# STM32H743 register map
File version: 2.4
CPU: CM7 r0p1, little endian, MPU, FPU, 4 interrupt priority bits
Registers are 32-bit, read-write, reset 0x0 unless marked. A register's access mark holds for its fields unless they carry their own. Offsets are from the block's base; [hi:lo] are bit positions.

## DMA2D — DMA2D（Chrom-Art 2D DMA 加速器）
Base 0x52001000
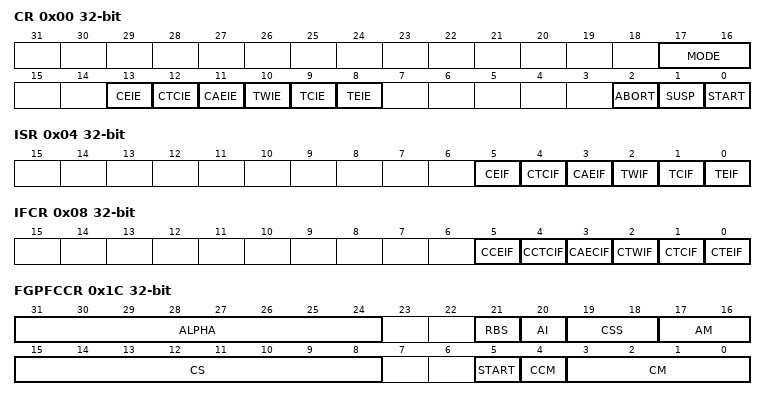
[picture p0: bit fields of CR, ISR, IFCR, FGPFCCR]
0x00 CR — DMA2D 控制寄存器
  [17:16] MODE — DMA2D 模式 此位由软件置位和清零。传输进行期间不可修改。
  [13] CEIE — 配置错误中断使能 此位由软件置位和清零。
  [12] CTCIE — CLUT 传输完成中断使能 此位由软件置位和清零。
  [11] CAEIE — CLUT 访问错误中断使能 此位由软件置位和清零。
  [10] TWIE — 传输水印中断使能 此位由软件置位和清零。
  [9] TCIE — 传输完成中断使能 此位由软件置位和清零。
  [8] TEIE — 传输错误中断使能 此位由软件置位和清零。
  [2] ABORT — 中止 将此位置 1 可中止当前传输。此位由软件置位，并在 START 位被硬件清零时由硬件自动清零。
  [1] SUSP — 暂停 将此位置 1 可暂停当前传输。此位由软件置位和清零。当 START 位被硬件清零时，此位由硬件自动清零。
  [0] START — 启动 将此位置 1 可根据各配置寄存器中加载的参数启动 DMA2D 传输
0x04 ISR ro — DMA2D 中断状态寄存器
  [5] CEIF — 配置错误中断标志 当 DMA2D_CR、DMA2DFGPFCCR 或 DMA2D_BGPFCCR 的 START 位置 1 但配置有误时，此位置 1。
  [4] CTCIF — CLUT 传输完成中断标志 当 CLUT 从系统存储区复制到 DMA2D 内部存储器完成时，此位置 1。
  [3] CAEIF — CLUT 访问错误中断标志 当 CLUT 正在从系统存储器自动复制到 DMA2D 内部存储器期间，CPU 访问了 CLUT 时，此位置 1。
  [2] TWIF — 传输水印中断标志 当水印行的最后一个像素传输完成时，此位置 1。
  [1] TCIF — 传输完成中断标志 当 DMA2D 传输操作完成（仅限数据传输）时，此位置 1。
  [0] TEIF — 传输错误中断标志 当 DMA 传输（数据传输或自动 CLUT 加载）期间发生错误时，此位置 1。
0x08 IFCR — DMA2D 中断标志清零寄存器
  [5] CCEIF — 清除配置错误中断标志 将此位写 1 可清零 DMA2D_ISR 寄存器中的 CEIF 标志
  [4] CCTCIF — 清除 CLUT 传输完成中断标志 将此位写 1 可清零 DMA2D_ISR 寄存器中的 CTCIF 标志
  [3] CAECIF — 清除 CLUT 访问错误中断标志 将此位写 1 可清零 DMA2D_ISR 寄存器中的 CAEIF 标志
  [2] CTWIF — 清除传输水印中断标志 将此位写 1 可清零 DMA2D_ISR 寄存器中的 TWIF 标志
  [1] CTCIF — 清除传输完成中断标志 将此位写 1 可清零 DMA2D_ISR 寄存器中的 TCIF 标志
  [0] CTEIF — 清除传输错误中断标志 将此位写 1 可清零 DMA2D_ISR 寄存器中的 TEIF 标志
0x0C FGMAR — DMA2D 前景层存储器地址寄存器
  [31:0] MA — 存储器地址 前景图像数据的存放地址。此寄存器仅在数据传输禁用时可写。一旦数据传输开始，此寄存器即为只读。地址对齐方式必须与所选图像格式匹配，例如：32 位每像素格式必须 32 位对齐，16 位每像素格式必须 16 位对齐，4 位每像素格式必须 8 位对齐。
0x10 FGOR — DMA2D 前景层偏移寄存器
  [13:0] LO — 行偏移 前景层的行偏移量，以像素为单位。该值用于生成地址，在每行末尾累加以确定下一行的起始地址。这些位仅在数据传输禁用时可写。一旦数据传输开始，即变为只读。若图像格式为 4 位每像素，行偏移必须为偶数。
0x14 BGMAR — DMA2D 背景层存储器地址寄存器
  [31:0] MA — 存储器地址 背景图像数据的存放地址。此寄存器仅在数据传输禁用时可写。一旦数据传输开始，此寄存器即为只读。地址对齐方式必须与所选图像格式匹配，例如：32 位每像素格式必须 32 位对齐，16 位每像素格式必须 16 位对齐，4 位每像素格式必须 8 位对齐。
0x18 BGOR — DMA2D 背景层偏移寄存器
  [13:0] LO — 行偏移 背景图像的行偏移量，以像素为单位。该值用于地址生成，在每行末尾累加以确定下一行的起始地址。这些位仅在数据传输禁用时可写。一旦数据传输开始，即变为只读。若图像格式为 4 位每像素，行偏移必须为偶数。
0x1C FGPFCCR — DMA2D 前景层像素格式转换控制寄存器
  [31:24] ALPHA — Alpha 值 这些位定义一个固定的 Alpha 通道值，根据 AM[1:0] 位所选的 Alpha 模式，该值可替换原始 Alpha 值或与原始 Alpha 值相乘。这些位仅在数据传输禁用时可写。一旦传输开始，即变为只读。
  [21] RBS — 红蓝交换 此位允许交换 R 和 B 通道以支持 BGR 或 ABGR 颜色格式。一旦传输开始，此位即为只读。
  [20] AI — Alpha 取反 此位将 Alpha 值取反。一旦传输开始，此位即为只读。
  [19:18] CSS — 色度子采样 这些位定义 YCbCr 颜色模式下的色度子采样模式。一旦传输开始，这些位即为只读。其他值：无意义
  [17:16] AM — Alpha 模式 这些位选择前景图像使用的 Alpha 通道值。仅在数据传输禁用时可写。一旦传输开始，即变为只读。其他配置：无意义
  [15:8] CS — CLUT 大小 这些位定义前景图像所用 CLUT 的大小。一旦 CLUT 传输开始，此字段即为只读。CLUT 条目数量等于 CS[7:0] + 1。
  [5] START — 启动 将此位置 1 可启动 CLUT 的自动加载。此位在以下情况下由硬件自动清零：传输结束时；用户应用程序通过置位 DMA2D_CR 中的 ABORT 位中止传输时；发生传输错误时；由于配置错误或另一传输操作（数据传输或后台 CLUT 自动传输）正在进行而导致传输未能启动时。
  [4] CCM — CLUT 颜色模式 此位定义 CLUT 的颜色格式。仅在传输禁用时可写。一旦 CLUT 传输开始，此位即变为只读。
  [3:0] CM — 颜色模式 这些位定义前景图像的颜色格式。仅在数据传输禁用时可写。一旦传输开始，即变为只读。其他值：无意义
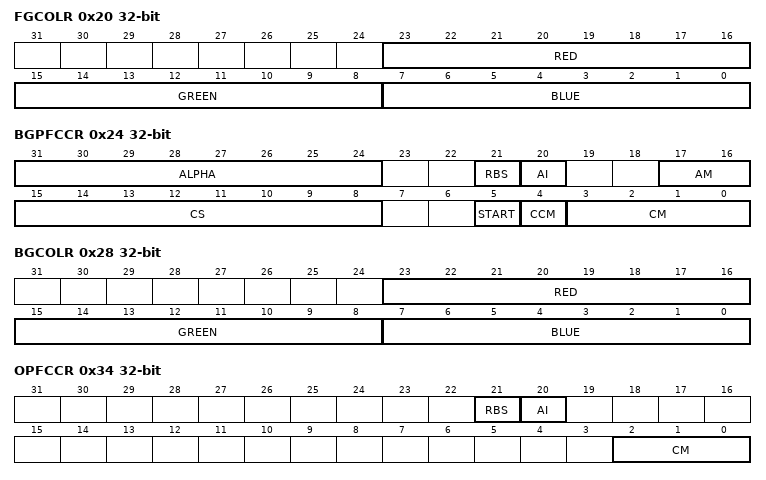
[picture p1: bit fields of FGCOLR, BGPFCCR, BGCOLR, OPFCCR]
0x20 FGCOLR — DMA2D 前景层颜色寄存器
  [23:16] RED — 红色分量 这些位定义前景图像在 A4 或 A8 模式下的红色分量值。仅在数据传输禁用时可写。一旦传输开始，即变为只读。
  [15:8] GREEN — 绿色分量 这些位定义前景图像在 A4 或 A8 模式下的绿色分量值。仅在数据传输禁用时可写。一旦传输开始，即变为只读。
  [7:0] BLUE — 蓝色分量 这些位定义前景图像在 A4 或 A8 模式下的蓝色分量值。仅在数据传输禁用时可写。一旦传输开始，即变为只读。
0x24 BGPFCCR — DMA2D 背景层像素格式转换控制寄存器
  [31:24] ALPHA — Alpha 值 这些位定义一个固定的 Alpha 通道值，根据 AM[1:0] 位所选的 Alpha 模式，该值可替换原始 Alpha 值或与原始 Alpha 值相乘。这些位仅在数据传输禁用时可写。一旦传输开始，即变为只读。
  [21] RBS — 红蓝交换 此位允许交换 R 和 B 通道以支持 BGR 或 ABGR 颜色格式。一旦传输开始，此位即为只读。
  [20] AI — Alpha 取反 此位将 Alpha 值取反。一旦传输开始，此位即为只读。
  [17:16] AM — Alpha 模式 这些位定义背景图像使用的 Alpha 通道值。仅在数据传输禁用时可写。一旦传输开始，即变为只读。其他值：无意义
  [15:8] CS — CLUT 大小 这些位定义背景层所用 CLUT 的大小。一旦 CLUT 传输开始，此字段即为只读。CLUT 条目数量等于 CS[7:0] + 1。
  [5] START — 启动 将此位置 1 可启动 CLUT 的自动加载。此位在以下情况下由硬件自动清零：传输结束时；用户应用程序通过置位 DMA2D_CR 中的 ABORT 位中止传输时；发生传输错误时；由于配置错误或另一传输操作（数据传输或后台 CLUT 自动传输）正在进行而导致传输未能启动时。
  [4] CCM — CLUT 颜色模式 这些位定义 CLUT 的颜色格式。仅在传输禁用时可写。一旦 CLUT 传输开始，此位即变为只读。
  [3:0] CM — 颜色模式 这些位定义背景图像的颜色格式。仅在数据传输禁用时可写。一旦传输开始，即变为只读。其他值：无意义
0x28 BGCOLR — DMA2D 背景层颜色寄存器
  [23:16] RED — 红色分量 这些位定义背景层在 A4 或 A8 模式下的红色分量值。仅在数据传输禁用时可写。一旦传输开始，即变为只读。
  [15:8] GREEN — 绿色分量 这些位定义背景层在 A4 或 A8 模式下的绿色分量值。仅在数据传输禁用时可写。一旦传输开始，即变为只读。
  [7:0] BLUE — 蓝色分量 这些位定义背景层在 A4 或 A8 模式下的蓝色分量值。仅在数据传输禁用时可写。一旦传输开始，即变为只读。
0x2C FGCMAR — DMA2D 前景层 CLUT 存储器地址寄存器
  [31:0] MA — 存储器地址 前景图像专用 CLUT 数据的存放地址。此寄存器仅在无传输进行时可写。一旦 CLUT 传输开始，此寄存器即为只读。若前景 CLUT 格式为 32 位，地址必须 32 位对齐。
0x30 BGCMAR — DMA2D 背景层 CLUT 存储器地址寄存器
  [31:0] MA — 存储器地址 背景图像专用 CLUT 数据的存放地址。此寄存器仅在无传输进行时可写。一旦 CLUT 传输开始，此寄存器即为只读。若背景 CLUT 格式为 32 位，地址必须 32 位对齐。
0x34 OPFCCR — DMA2D 输出层像素格式转换控制寄存器
  [21] RBS — 红蓝交换 此位允许交换 R 和 B 通道以支持 BGR 或 ABGR 颜色格式。一旦传输开始，此位即为只读。
  [20] AI — Alpha 取反 此位将 Alpha 值取反。一旦传输开始，此位即为只读。
  [2:0] CM — 颜色模式 这些位定义输出图像的颜色格式。仅在数据传输禁用时可写。一旦传输开始，即变为只读。其他值：无意义
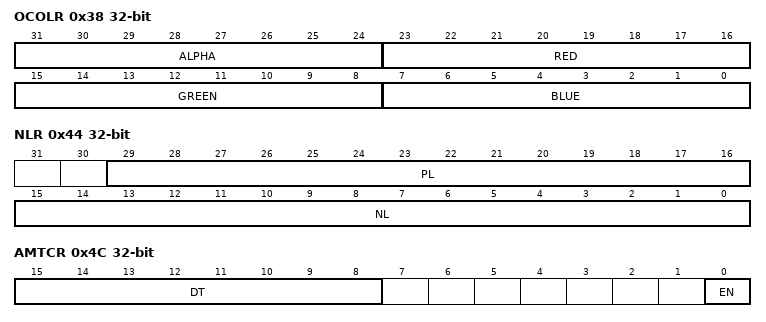
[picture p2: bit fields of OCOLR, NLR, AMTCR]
0x38 OCOLR — DMA2D 输出层颜色寄存器
  [31:24] ALPHA — Alpha 通道值 这些位定义输出颜色的 Alpha 通道值。仅在数据传输禁用时可写。一旦传输开始，即变为只读。
  [23:16] RED — 红色分量 这些位定义输出图像的红色分量值。仅在数据传输禁用时可写。一旦传输开始，即变为只读。
  [15:8] GREEN — 绿色分量 这些位定义输出图像的绿色分量值。仅在数据传输禁用时可写。一旦传输开始，即变为只读。
  [7:0] BLUE — 蓝色分量 这些位定义输出图像的蓝色分量值。仅在数据传输禁用时可写。一旦传输开始，即变为只读。
0x3C OMAR — DMA2D 输出层存储器地址寄存器
  [31:0] MA — 存储器地址 输出 FIFO 数据的存放地址。这些位仅在数据传输禁用时可写。一旦传输开始，即变为只读。地址对齐方式必须与所选图像格式匹配，例如：32 位每像素格式必须 32 位对齐，16 位每像素格式必须 16 位对齐。
0x40 OOR — DMA2D 输出层偏移寄存器
  [13:0] LO — 行偏移 输出图像的行偏移量，以像素为单位。该值用于地址生成，在每行末尾累加以确定下一行的起始地址。这些位仅在数据传输禁用时可写。一旦传输开始，即变为只读。
0x44 NLR — DMA2D 行数寄存器
  [29:16] PL — 每行像素数 待传输区域每行的像素数量。这些位仅在数据传输禁用时可写。一旦传输开始，即变为只读。若任一输入图像格式为 4 位每像素，每行像素数必须为偶数。
  [15:0] NL — 行数 待传输区域的行数。这些位仅在数据传输禁用时可写。一旦传输开始，即变为只读。
0x48 LWR — DMA2D 行水印寄存器
  [15:0] LW — 行水印 这些位用于配置产生中断的行水印值。当水印行的最后一个像素传输完成时，将触发中断。这些位仅在数据传输禁用时可写。一旦传输开始，即变为只读。
0x4C AMTCR — DMA2D AXI 主接口定时器配置寄存器
  [15:8] DT — 死区时间 插入到 AXI 主端口两次连续访问之间的死区时间值，以 AXI 时钟周期为单位。这些位表示两次连续 AXI 访问之间的最小保证时钟周期数。
  [0] EN — 使能 使能死区时间功能。
